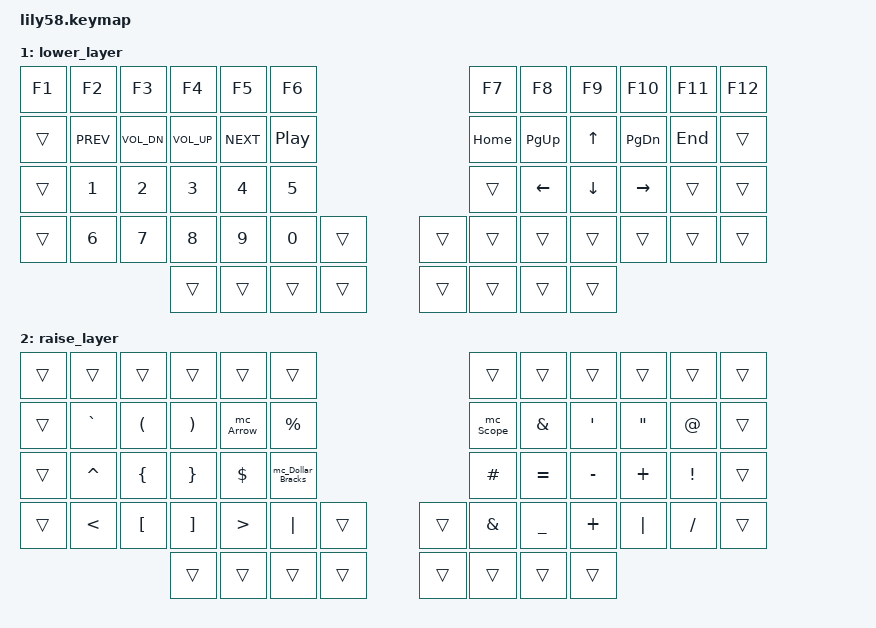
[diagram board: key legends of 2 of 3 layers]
#include <behaviors.dtsi>
#include <dt-bindings/zmk/keys.h>
#include <dt-bindings/zmk/bt.h>
#include <dt-bindings/zmk/ext_power.h>
#include "58keys.h"

/ {

    behaviors {

        #include "behaviors.dtsi"
    };

    combos {
        #include "combos.dtsi"
    };

    macros {
        #include "macros.dtsi"
    };


    keymap {
        compatible = "zmk,keymap";

        default_layer {
            bindings = <
        &kp ESC   &kp N1 &kp N2 &kp N3   &kp N4   &kp N5                     &kp N6 &kp N7   &kp N8    &kp N9  &kp N0   &kp BSPC
        &kp TAB   &kp Q  &kp W  &kp E    &kp R    &kp T                      &kp Y  &kp U    &kp I     &kp O   &kp P    &kp MINUS
        &kp LCTRL HRML( A,   S,     D,       F)   &kp G                      &kp H  HRML(J,      K,        L,   SEMI)   &kp SQT
        &kp LSHFT &kp Z  &kp X  &kp C    &kp V    &kp B  &kp LBKT   &kp RBKT &kp N  &kp M    &kp COMMA &kp DOT &kp FSLH &kp RCTRL
                           &kp LALT   &kp LGUI    &mo NAV    &kp RET       &kp SPACE    &mo SYM    &kp DEL    &kp RALT
            >;
        };

        lower_layer {
            bindings = <
&kp F1    &kp F2      &kp F3   &kp F4  &kp F5  &kp F6                      &kp F7    &kp F8 &kp F9 &kp F10 &kp F11 &kp F12
&trans    &kp C_PREV  &kp C_VOL_DN &kp C_VOL_UP &kp C_NEXT  &kp C_PP       &kp HOME    &kp PG_UP    &kp UP    &kp PG_DN    &kp END  &trans
&trans    &kp N1     &kp N2        &kp N3      &kp N4     &kp N5           &trans    &kp LEFT  &kp DOWN    &kp RIGHT      &trans    &trans         
&trans    &kp N6     &kp N7        &kp N8      &kp N9     &kp N0  &trans  &trans    &trans   &trans    &trans     &trans    &trans    &trans
                           &trans    &trans    &trans    &trans           &trans    &trans    &trans    &trans
            >;
        };

        raise_layer {
// ------------------------------------------------------------------------------------------------------------
// |       |     |     |      |      |      |                   |      |       |       |      |       |       |
// |   `   |  1  |  2  |  3   |  4   |  5   |                   |  6   |   7   |   8   |  9   |   0   |       |
// |   F1  |  F2 |  F3 |  F4  |  F5  |  F6  |                   |      |   <-  |   v   |  ^   |  ->   |       |
// |   F7  |  F8 |  F9 |  F10 |  F11 |  F12 |        |  |       |  +   |   -   |   =   |  [   |   ]   |   \   |
//                     |      |      |      |        |  |       |      |       |       |
            bindings = <
&trans    &trans      &trans     &trans   &trans  &trans                      &trans      &trans    &trans    &trans   &trans    &trans
&trans    &kp GRAVE   &kp LPAR   &kp RPAR &mc_Arrow  &kp PRCNT                &mc_Scope  &kp AMPS  &kp QUOT   &kp DQT   &kp AT  &trans
&trans    &kp CARET   &kp LBRC   &kp RBRC   &kp DLLR   &mc_Dollar_Bracks      &kp HASH  &kp EQUAL  &kp MINUS  &kp PLUS   &kp EXCL  &trans
&trans    &kp LT      &kp LBKT   &kp RBKT    &kp GT    &kp PIPE  &trans    &trans  &kp AMPS   &kp UNDER  &kp PLUS   &kp PIPE  &kp FSLH &trans
                            &trans  &trans  &trans    &trans   &trans    &trans      &trans    &trans
            >;
        };
    };
};
